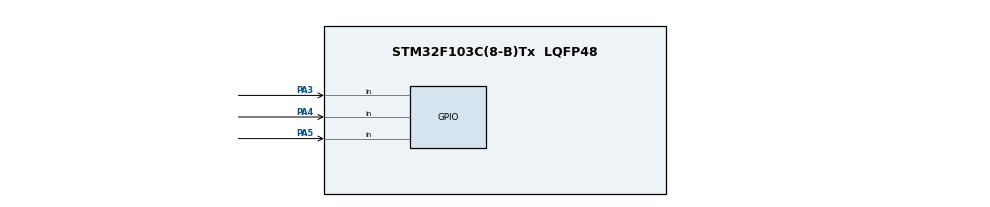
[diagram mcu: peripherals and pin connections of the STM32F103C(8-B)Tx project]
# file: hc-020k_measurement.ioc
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Mcu.Family=STM32F1
Mcu.Name=STM32F103C(8-B)Tx
Mcu.Package=LQFP48
NVIC.PriorityGroup=NVIC_PRIORITYGROUP_4
PA13.Mode=Serial_Wire
PA13.Signal=SYS_JTMS-SWDIO
PA14.Mode=Serial_Wire
PA14.Signal=SYS_JTCK-SWCLK
PA3.Signal=GPIO_Input
PA4.Signal=GPIO_Input
PA5.Signal=GPIO_Input
PD0-OSC_IN.Mode=HSE-External-Oscillator
PD0-OSC_IN.Signal=RCC_OSC_IN
PD1-OSC_OUT.Mode=HSE-External-Oscillator
PD1-OSC_OUT.Signal=RCC_OSC_OUT
ProjectManager.HeapSize=0x200
ProjectManager.StackSize=0x400
ProjectManager.TargetToolchain=MDK-ARM V5.27
RCC.APB1Freq_Value=8000000
RCC.APB2Freq_Value=8000000
TIM2.Period=0xffff-1
TIM2.Prescaler=8000-1
VP_TIM2_VS_ClockSourceINT.Mode=Internal
board=custom

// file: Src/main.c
/* USER CODE BEGIN Header */
/**
  ******************************************************************************
  * @file           : main.c
  * @brief          : Main program body
  ******************************************************************************
  * @attention
  *
  * <h2><center>&copy; Copyright (c) 2020 STMicroelectronics.
  * All rights reserved.</center></h2>
  *
  * This software component is licensed by ST under BSD 3-Clause license,
  * the "License"; You may not use this file except in compliance with the
  * License. You may obtain a copy of the License at:
  *                        opensource.org/licenses/BSD-3-Clause
  *
  ******************************************************************************
  */
/* USER CODE END Header */

#include "main.h"

/* USER CODE BEGIN PD */

 uint32_t freq,increment;
/* USER CODE END PD */

TIM_HandleTypeDef htim2;

void SystemClock_Config(void);
static void MX_GPIO_Init(void);
static void MX_TIM2_Init(void);

/* USER CODE BEGIN 0 */
void read_freq (void)
{
	htim2.Instance->CNT = 0;  // set the count to 0

	while ((htim2.Instance->CNT) < 1000)  // while the count is less than 1000 ms
	{
		while (!(HAL_GPIO_ReadPin (GPIOA, GPIO_PIN_3)));  // wait for the pin to go high

		while ((HAL_GPIO_ReadPin (GPIOA, GPIO_PIN_3)));  // wait for the pin to go low

		increment++;  // increment the variable
	}

	freq = increment;  // freq = number of times pin goes high and low in  second

	increment = 0;
}

/* USER CODE END 0 */

int main(void)
{

  /* MCU Configuration--------------------------------------------------------*/

  /* Reset of all peripherals, Initializes the Flash interface and the Systick. */
  HAL_Init();

  /* Configure the system clock */
  SystemClock_Config();

  /* Initialize all configured peripherals */
  MX_GPIO_Init();
  MX_TIM2_Init();
  /* USER CODE BEGIN 2 */
	HAL_TIM_Base_Start(&htim2);
  /* USER CODE END 2 */

  /* Infinite loop */
  /* USER CODE BEGIN WHILE */
  while (1)
  {
				read_freq();
    /* USER CODE END WHILE */

  }
}

void SystemClock_Config(void)
{
  RCC_OscInitTypeDef RCC_OscInitStruct = {0};
  RCC_ClkInitTypeDef RCC_ClkInitStruct = {0};

  /** Initializes the CPU, AHB and APB busses clocks
  */
  RCC_OscInitStruct.OscillatorType = RCC_OSCILLATORTYPE_HSI;
  RCC_OscInitStruct.HSIState = RCC_HSI_ON;
  RCC_OscInitStruct.HSICalibrationValue = RCC_HSICALIBRATION_DEFAULT;
  RCC_OscInitStruct.PLL.PLLState = RCC_PLL_NONE;
  if (HAL_RCC_OscConfig(&RCC_OscInitStruct) != HAL_OK)
  {
    Error_Handler();
  }
  /** Initializes the CPU, AHB and APB busses clocks
  */
  RCC_ClkInitStruct.ClockType = RCC_CLOCKTYPE_HCLK|RCC_CLOCKTYPE_SYSCLK
                              |RCC_CLOCKTYPE_PCLK1|RCC_CLOCKTYPE_PCLK2;
  RCC_ClkInitStruct.SYSCLKSource = RCC_SYSCLKSOURCE_HSI;
  RCC_ClkInitStruct.AHBCLKDivider = RCC_SYSCLK_DIV1;
  RCC_ClkInitStruct.APB1CLKDivider = RCC_HCLK_DIV1;
  RCC_ClkInitStruct.APB2CLKDivider = RCC_HCLK_DIV1;

  if (HAL_RCC_ClockConfig(&RCC_ClkInitStruct, FLASH_LATENCY_0) != HAL_OK)
  {
    Error_Handler();
  }
}

static void MX_TIM2_Init(void)
{

  TIM_ClockConfigTypeDef sClockSourceConfig = {0};
  TIM_MasterConfigTypeDef sMasterConfig = {0};

  htim2.Instance = TIM2;
  htim2.Init.Prescaler = 8000-1;
  htim2.Init.CounterMode = TIM_COUNTERMODE_UP;
  htim2.Init.Period = 0xffff-1;
  htim2.Init.ClockDivision = TIM_CLOCKDIVISION_DIV1;
  htim2.Init.AutoReloadPreload = TIM_AUTORELOAD_PRELOAD_DISABLE;
  if (HAL_TIM_Base_Init(&htim2) != HAL_OK)
  {
    Error_Handler();
  }
  sClockSourceConfig.ClockSource = TIM_CLOCKSOURCE_INTERNAL;
  if (HAL_TIM_ConfigClockSource(&htim2, &sClockSourceConfig) != HAL_OK)
  {
    Error_Handler();
  }
  sMasterConfig.MasterOutputTrigger = TIM_TRGO_RESET;
  sMasterConfig.MasterSlaveMode = TIM_MASTERSLAVEMODE_DISABLE;
  if (HAL_TIMEx_MasterConfigSynchronization(&htim2, &sMasterConfig) != HAL_OK)
  {
    Error_Handler();
  }

}

static void MX_GPIO_Init(void)
{
  GPIO_InitTypeDef GPIO_InitStruct = {0};

  /* GPIO Ports Clock Enable */
  __HAL_RCC_GPIOD_CLK_ENABLE();
  __HAL_RCC_GPIOA_CLK_ENABLE();

  /*Configure GPIO pins : PA3 PA4 PA5 */
  GPIO_InitStruct.Pin = GPIO_PIN_3|GPIO_PIN_4|GPIO_PIN_5;
  GPIO_InitStruct.Mode = GPIO_MODE_INPUT;
  GPIO_InitStruct.Pull = GPIO_NOPULL;
  HAL_GPIO_Init(GPIOA, &GPIO_InitStruct);

}

void Error_Handler(void)
{
}

/************************ (C) COPYRIGHT STMicroelectronics *****END OF FILE****/
